# AT32F415xx register map
Vendor: Keil; Series: AT32F415; File version: 1.0
CPU: CM4 r0p1, little endian, no MPU, FPU, 4 interrupt priority bits
Registers are 32-bit, read-write, reset 0x0 unless marked. A register's access mark holds for its fields unless they carry their own. Offsets are from the block's base; [hi:lo] are bit positions.

## IWDG — Independent watchdog
Base 0x40003000
0x00 KEY — Key register (IWDG_KEY)
  [15:0] KEY — Key value
0x04 PR — Prescaler register (IWDG_PR)
  [2:0] PR — Prescaler divider
0x08 RLD reset 0xFFF — Reload register (IWDG_RLR)
  [11:0] RLD — Watchdog counter reload value
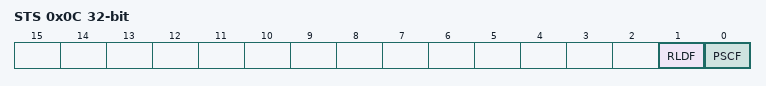
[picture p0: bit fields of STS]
0x0C STS ro — Status register (IWDG_SR)
  [1] RLDF — Watchdog counter reload value update
  [0] PSCF — Watchdog prescaler value update

## WWDG — Window watchdog
Base 0x40002C00
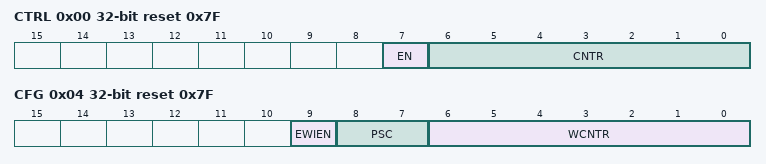
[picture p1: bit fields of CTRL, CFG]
0x00 CTRL reset 0x7F — Control register (WWDG_CR)
  [7] EN — Activation bit
  [6:0] CNTR — 7-bit counter (MSB to LSB)
0x04 CFG reset 0x7F — Configuration register (WWDG_CFG)
  [9] EWIEN — Early Wakeup Interrupt
  [8:7] PSC — Timer Base
  [6:0] WCNTR — 7-bit window value
0x08 STS — Status register (WWDG_SR)
  [0] EWIF — Early Wakeup Interrupt

## TMR9 — General purpose timer
Base 0x40014C00
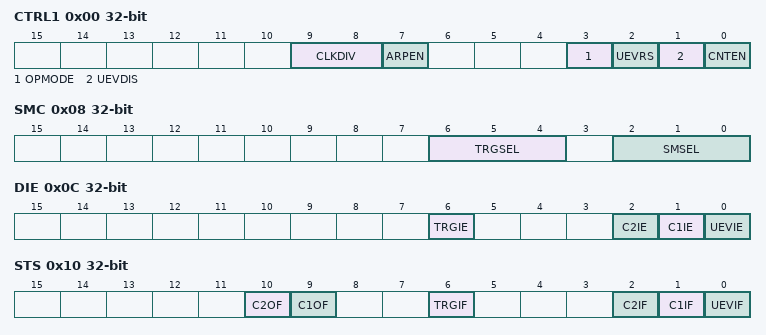
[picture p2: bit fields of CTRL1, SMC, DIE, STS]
0x00 CTRL1 — control register 1
  [9:8] CLKDIV — Clock division
  [7] ARPEN — Auto-reload preload enable
  [3] OPMODE — One-pulse mode
  [2] UEVRS — Update request source
  [1] UEVDIS — Update disable
  [0] CNTEN — Counter enable
0x08 SMC — slave mode control register
  [6:4] TRGSEL — Trigger selection
  [2:0] SMSEL — Slave mode selection
0x0C DIE — DMA/Interrupt enable register
  [6] TRGIE — Trigger interrupt enable
  [2] C2IE — Capture/Compare 2 interrupt enable
  [1] C1IE — Capture/Compare 1 interrupt enable
  [0] UEVIE — Update interrupt enable
0x10 STS — status register
  [10] C2OF — Capture/compare 2 overcapture flag
  [9] C1OF — Capture/Compare 1 overcapture flag
  [6] TRGIF — Trigger interrupt flag
  [2] C2IF — Capture/Compare 2 interrupt flag
  [1] C1IF — Capture/compare 1 interrupt flag
  [0] UEVIF — Update interrupt flag
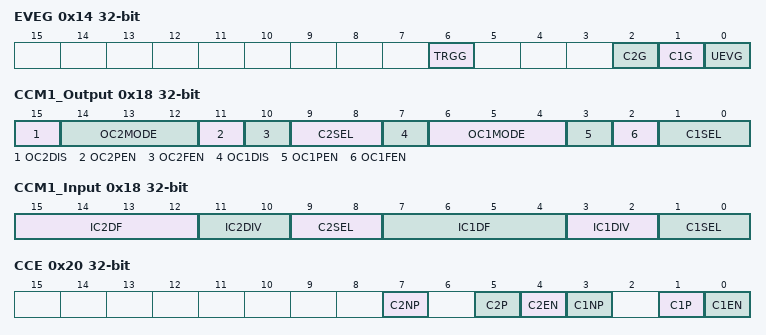
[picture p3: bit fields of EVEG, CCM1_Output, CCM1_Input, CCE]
0x14 EVEG wo — event generation register
  [6] TRGG — Trigger generation
  [2] C2G — Capture/compare 2 generation
  [1] C1G — Capture/compare 1 generation
  [0] UEVG — Update generation
0x18 CCM1_Output — capture/compare mode register 1 (output mode)
  [15] OC2DIS — Output compare 2 clear enable
  [14:12] OC2MODE — Output Compare 2 mode
  [11] OC2PEN — Output Compare 2 preload enable
  [10] OC2FEN — Output Compare 2 fast enable
  [9:8] C2SEL — Capture/Compare 2 selection
  [7] OC1DIS — Output compare 1 clear enable
  [6:4] OC1MODE — Output Compare 1 mode
  [3] OC1PEN — Output Compare 1 preload enable
  [2] OC1FEN — Output Compare 1 fast enable
  [1:0] C1SEL — Capture/Compare 1 selection
0x18 CCM1_Input (alternate view of CCM1_Output) — capture/compare mode register 1 (input mode)
  [15:12] IC2DF — Input capture 2 filter
  [11:10] IC2DIV — Input capture 2 prescaler
  [9:8] C2SEL — Capture/Compare 2 selection
  [7:4] IC1DF — Input capture 1 filter
  [3:2] IC1DIV — Input capture 1 prescaler
  [1:0] C1SEL — Capture/Compare 1 selection
0x20 CCE — capture/compare enable register
  [7] C2NP — Capture/Compare 2 output Polarity
  [5] C2P — Capture/Compare 2 output Polarity
  [4] C2EN — Capture/Compare 2 output enable
  [3] C1NP — Capture/Compare 1 output Polarity
  [1] C1P — Capture/Compare 1 output Polarity
  [0] C1EN — Capture/Compare 1 output enable
0x24 CNT — counter
  [15:0] CNT — counter value
0x28 DIV — prescaler
  [15:0] DIV — Prescaler value
0x2C AR — auto-reload register
  [15:0] AR — Auto-reload value
0x34 CC1 — capture/compare register 1
  [15:0] CC1 — Capture/Compare 1 value
0x38 CC2 — capture/compare register 2
  [15:0] CC2 — Capture/Compare 2 value

## TMR10 — General purpose timer
Base 0x40015000
Same registers: TMR11 0x40015400
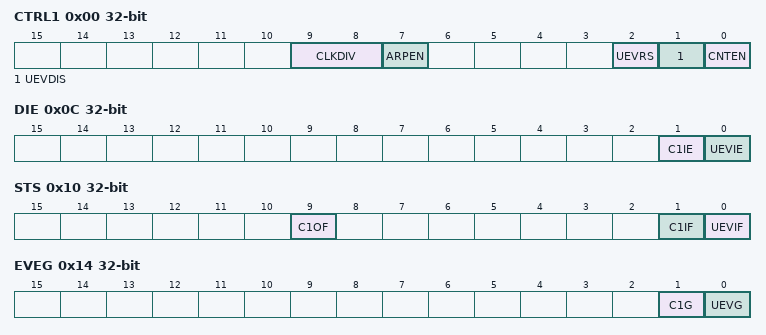
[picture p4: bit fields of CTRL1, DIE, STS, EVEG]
0x00 CTRL1 — control register 1
  [9:8] CLKDIV — Clock division
  [7] ARPEN — Auto-reload preload enable
  [2] UEVRS — Update request source
  [1] UEVDIS — Update disable
  [0] CNTEN — Counter enable
0x0C DIE — DMA/Interrupt enable register
  [1] C1IE — Capture/Compare 1 interrupt enable
  [0] UEVIE — Update interrupt enable
0x10 STS — status register
  [9] C1OF — Capture/Compare 1 overcapture flag
  [1] C1IF — Capture/compare 1 interrupt flag
  [0] UEVIF — Update interrupt flag
0x14 EVEG — event generation register
  [1] C1G — Capture/compare 1 generation
  [0] UEVG — Update generation
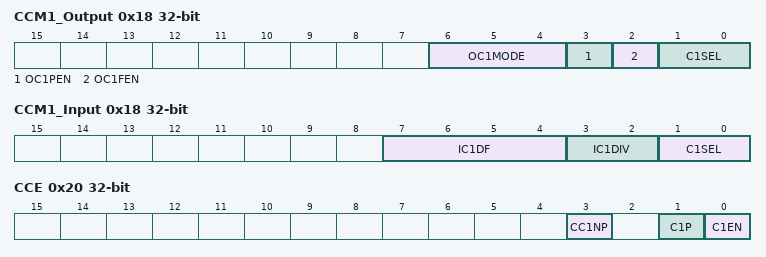
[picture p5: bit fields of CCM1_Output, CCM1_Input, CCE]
0x18 CCM1_Output — capture/compare mode register (output mode)
  [6:4] OC1MODE — Output Compare 1 mode
  [3] OC1PEN — Output Compare 1 preload enable
  [2] OC1FEN — Output Compare 1 fast enable
  [1:0] C1SEL — Capture/Compare 1 selection
0x18 CCM1_Input (alternate view of CCM1_Output) — capture/compare mode register (input mode)
  [7:4] IC1DF — Input capture 1 filter
  [3:2] IC1DIV — Input capture 1 prescaler
  [1:0] C1SEL — Capture/Compare 1 selection
0x20 CCE — capture/compare enable register
  [3] CC1NP — Capture/Compare 1 output Polarity
  [1] C1P — Capture/Compare 1 output Polarity
  [0] C1EN — Capture/Compare 1 output enable
0x24 CNT — counter
  [15:0] CNT — counter value
0x28 DIV — prescaler
  [15:0] DIV — Prescaler value
0x2C AR — auto-reload register
  [15:0] AR — Auto-reload value
0x34 CC1 — capture/compare register 1
  [15:0] CC1 — Capture/Compare 1 value
